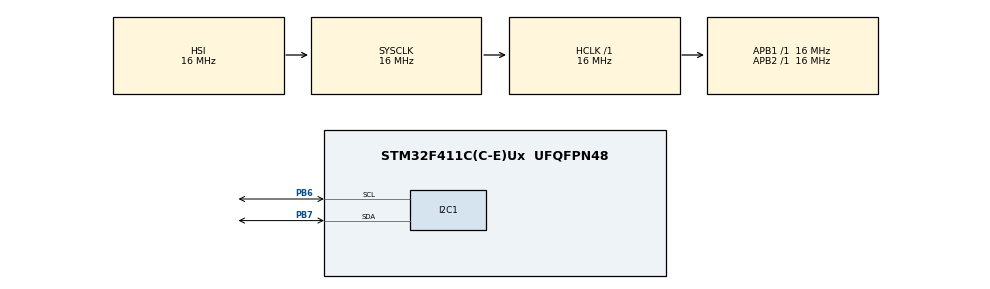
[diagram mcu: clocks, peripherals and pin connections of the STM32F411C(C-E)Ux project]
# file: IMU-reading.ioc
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Mcu.Family=STM32F4
Mcu.Name=STM32F411C(C-E)Ux
Mcu.Package=UFQFPN48
NVIC.PriorityGroup=NVIC_PRIORITYGROUP_4
PB6.Mode=I2C
PB6.Signal=I2C1_SCL
PB7.Mode=I2C
PB7.Signal=I2C1_SDA
ProjectManager.HeapSize=0x200
ProjectManager.StackSize=0x400
ProjectManager.TargetToolchain=STM32CubeIDE
RCC.AHBFreq_Value=16000000
RCC.APB1Freq_Value=16000000
RCC.APB2Freq_Value=16000000
RCC.CortexFreq_Value=16000000
RCC.HSE_VALUE=25000000
RCC.HSI_VALUE=16000000
RCC.LSE_VALUE=32768
RCC.SYSCLKFreq_VALUE=16000000
RCC.VCOOutputFreq_Value=192000000
board=custom

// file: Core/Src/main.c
/* USER CODE BEGIN Header */
/**
 ******************************************************************************
 * @file           : main.c
 * @brief          : Main program body
 ******************************************************************************
 * @attention
 *
 * Copyright (c) 2025 STMicroelectronics.
 * All rights reserved.
 *
 * This software is licensed under terms that can be found in the LICENSE file
 * in the root directory of this software component.
 * If no LICENSE file comes with this software, it is provided AS-IS.
 *
 ******************************************************************************
 */
/* USER CODE END Header */
#include "main.h"

/* USER CODE BEGIN Includes */
#include "lsm6dsox_reg.h"
#include "lis3mdl_reg.h"
/* USER CODE END Includes */

I2C_HandleTypeDef hi2c1;

/* USER CODE BEGIN PV */

uint8_t who_am_i1;

stmdev_ctx_t lsm6dsox_ctx;
stmdev_ctx_t lis3mdl_ctx;

uint8_t test_data = 0xAA;

float accel_x, accel_y, accel_z;
float gyro_x, gyro_y, gyro_z;
float mag_x, mag_y, mag_z;
/* USER CODE END PV */

void SystemClock_Config(void);
static void MX_GPIO_Init(void);
static void MX_I2C1_Init(void);
/* USER CODE BEGIN PFP */
// I2C read and write functions
int32_t platform_write(void *handle, uint8_t reg, const uint8_t *bufp,
		uint16_t len);
int32_t platform_read(void *handle, uint8_t reg, uint8_t *bufp, uint16_t len);

// Initialization functions
void LSM6DSOX_Init(void);
void LIS3MDL_Init(void);

// Sensor data read functions
void LSM6DSOX_ReadAccel(float *x, float *y, float *z);
void LSM6DSOX_ReadGyro(float *x, float *y, float *z);
void LIS3MDL_ReadMag(float *x, float *y, float *z);
/* USER CODE END PFP */

int main(void) {

	/* MCU Configuration--------------------------------------------------------*/

	/* Reset of all peripherals, Initializes the Flash interface and the Systick. */
	HAL_Init();

	/* Configure the system clock */
	SystemClock_Config();

	/* Initialize all configured peripherals */
	MX_GPIO_Init();
	MX_I2C1_Init();
	/* USER CODE BEGIN 2 */
	LSM6DSOX_Init();
	LIS3MDL_Init();
	/* USER CODE END 2 */

	/* Infinite loop */
	while (1) {
		// Variables for sensor readings

		// Read sensor data
		LSM6DSOX_ReadAccel(&accel_x, &accel_y, &accel_z);
		LSM6DSOX_ReadGyro(&gyro_x, &gyro_y, &gyro_z);
		LIS3MDL_ReadMag(&mag_x, &mag_y, &mag_z);

//		test_I2C_Communication();
		HAL_Delay(500);
	}
}

void SystemClock_Config(void) {
	RCC_OscInitTypeDef RCC_OscInitStruct = { 0 };
	RCC_ClkInitTypeDef RCC_ClkInitStruct = { 0 };

	/** Configure the main internal regulator output voltage
	 */
	__HAL_RCC_PWR_CLK_ENABLE();
	__HAL_PWR_VOLTAGESCALING_CONFIG(PWR_REGULATOR_VOLTAGE_SCALE1);

	/** Initializes the RCC Oscillators according to the specified parameters
	 * in the RCC_OscInitTypeDef structure.
	 */
	RCC_OscInitStruct.OscillatorType = RCC_OSCILLATORTYPE_HSI;
	RCC_OscInitStruct.HSIState = RCC_HSI_ON;
	RCC_OscInitStruct.HSICalibrationValue = RCC_HSICALIBRATION_DEFAULT;
	RCC_OscInitStruct.PLL.PLLState = RCC_PLL_NONE;
	if (HAL_RCC_OscConfig(&RCC_OscInitStruct) != HAL_OK) {
		Error_Handler();
	}

	/** Initializes the CPU, AHB and APB buses clocks
	 */
	RCC_ClkInitStruct.ClockType = RCC_CLOCKTYPE_HCLK | RCC_CLOCKTYPE_SYSCLK
			| RCC_CLOCKTYPE_PCLK1 | RCC_CLOCKTYPE_PCLK2;
	RCC_ClkInitStruct.SYSCLKSource = RCC_SYSCLKSOURCE_HSI;
	RCC_ClkInitStruct.AHBCLKDivider = RCC_SYSCLK_DIV1;
	RCC_ClkInitStruct.APB1CLKDivider = RCC_HCLK_DIV1;
	RCC_ClkInitStruct.APB2CLKDivider = RCC_HCLK_DIV1;

	if (HAL_RCC_ClockConfig(&RCC_ClkInitStruct, FLASH_LATENCY_0) != HAL_OK) {
		Error_Handler();
	}
}

static void MX_I2C1_Init(void) {

	hi2c1.Instance = I2C1;
	hi2c1.Init.ClockSpeed = 100000;
	hi2c1.Init.DutyCycle = I2C_DUTYCYCLE_2;
	hi2c1.Init.OwnAddress1 = 0;
	hi2c1.Init.AddressingMode = I2C_ADDRESSINGMODE_7BIT;
	hi2c1.Init.DualAddressMode = I2C_DUALADDRESS_DISABLE;
	hi2c1.Init.OwnAddress2 = 0;
	hi2c1.Init.GeneralCallMode = I2C_GENERALCALL_DISABLE;
	hi2c1.Init.NoStretchMode = I2C_NOSTRETCH_DISABLE;
	if (HAL_I2C_Init(&hi2c1) != HAL_OK) {
		Error_Handler();
	}

}

static void MX_GPIO_Init(void) {

	/* GPIO Ports Clock Enable */
	__HAL_RCC_GPIOB_CLK_ENABLE();

}

/* USER CODE BEGIN 4 */

void test_I2C_Communication() {
    HAL_StatusTypeDef status;

    // 1. Try sending a test byte to the LSM6DSOX address (default: 0x6A)
    uint8_t device_address = 0x6A << 1;  // Shifted for 7-bit address format

    status = HAL_I2C_Master_Transmit(&hi2c1, device_address, &test_data, 1, HAL_MAX_DELAY);

    if (status == HAL_OK) {
        char msg[] = "I2C Write OK\r\n";
//        HAL_UART_Transmit(&huart2, (uint8_t*)msg, sizeof(msg), HAL_MAX_DELAY);
    } else {
        char msg[] = "I2C Write FAIL\r\n";
        //HAL_UART_Transmit(&huart2, (uint8_t*)msg, sizeof(msg), HAL_MAX_DELAY);
    }
}

void LSM6DSOX_Init(void) {

    // Initialize context
    lsm6dsox_ctx.write_reg = platform_write;
    lsm6dsox_ctx.read_reg = platform_read;
    lsm6dsox_ctx.handle = &hi2c1;

    // Check WHO_AM_I register
    lsm6dsox_device_id_get(&lsm6dsox_ctx, &who_am_i1);
    if (who_am_i1 != LSM6DSOX_ID) {
       // while (1);
    }

    // Reset device
    lsm6dsox_reset_set(&lsm6dsox_ctx, PROPERTY_ENABLE);
    uint8_t reset;
    do {
        lsm6dsox_reset_get(&lsm6dsox_ctx, &reset);
    } while (reset);

    // Enable Block Data Update
    lsm6dsox_block_data_update_set(&lsm6dsox_ctx, PROPERTY_ENABLE);

    // Configure accelerometer (2g, 416 Hz)
    lsm6dsox_xl_data_rate_set(&lsm6dsox_ctx, LSM6DSOX_XL_ODR_417Hz);
    lsm6dsox_xl_full_scale_set(&lsm6dsox_ctx, LSM6DSOX_2g);

    // Configure gyroscope (2000 dps, 416 Hz)
    lsm6dsox_gy_data_rate_set(&lsm6dsox_ctx, LSM6DSOX_GY_ODR_417Hz);
    lsm6dsox_gy_full_scale_set(&lsm6dsox_ctx, LSM6DSOX_2000dps);

    printf("LSM6DSOX initialized.\n");
}

/**
 * @brief Initialize the LIS3MDL sensor.
 */
void LIS3MDL_Init(void) {
    uint8_t who_am_i;

    // Initialize context
    lis3mdl_ctx.write_reg = platform_write;
    lis3mdl_ctx.read_reg = platform_read;
    lis3mdl_ctx.handle = &hi2c1;

    // Check WHO_AM_I register
    lis3mdl_device_id_get(&lis3mdl_ctx, &who_am_i);
  //  if (who_am_i != LIS3MDL_ID) {
  //      printf("LIS3MDL not detected! WHO_AM_I=0x%02X\n", who_am_i);
  //      while (1);
  //  }

    // Reset device
    lis3mdl_reset_set(&lis3mdl_ctx, PROPERTY_ENABLE);
    uint8_t reset;
    do {
        lis3mdl_reset_get(&lis3mdl_ctx, &reset);
    } while (reset);

    // Configure magnetometer (Ultra-high performance, 10 Hz)
    lis3mdl_block_data_update_set(&lis3mdl_ctx, PROPERTY_ENABLE);
    lis3mdl_data_rate_set(&lis3mdl_ctx, LIS3MDL_UHP_10Hz);
    lis3mdl_full_scale_set(&lis3mdl_ctx, LIS3MDL_4_GAUSS);
    lis3mdl_operating_mode_set(&lis3mdl_ctx, LIS3MDL_CONTINUOUS_MODE);

    printf("LIS3MDL initialized.\n");
}
/**
 * @brief Read accelerometer data.
 */
void LSM6DSOX_ReadAccel(float *x, float *y, float *z) {
    int16_t data_raw[3];
    lsm6dsox_acceleration_raw_get(&lsm6dsox_ctx, data_raw);
    *x = lsm6dsox_from_fs2_to_mg(data_raw[0]) / 1000.0f;
    *y = lsm6dsox_from_fs2_to_mg(data_raw[1]) / 1000.0f;
    *z = lsm6dsox_from_fs2_to_mg(data_raw[2]) / 1000.0f;
}

/**
 * @brief Read gyroscope data.
 */
void LSM6DSOX_ReadGyro(float *x, float *y, float *z) {
    int16_t data_raw[3];
    lsm6dsox_angular_rate_raw_get(&lsm6dsox_ctx, data_raw);
    *x = lsm6dsox_from_fs2000_to_mdps(data_raw[0]) / 1000.0f;
    *y = lsm6dsox_from_fs2000_to_mdps(data_raw[1]) / 1000.0f;
    *z = lsm6dsox_from_fs2000_to_mdps(data_raw[2]) / 1000.0f;
}

/**
 * @brief Read magnetometer data.
 */
void LIS3MDL_ReadMag(float *x, float *y, float *z) {
    int16_t data_raw[3];
    lis3mdl_magnetic_raw_get(&lis3mdl_ctx, data_raw);
    *x = lis3mdl_from_fs4_to_gauss(data_raw[0]);
    *y = lis3mdl_from_fs4_to_gauss(data_raw[1]);
    *z = lis3mdl_from_fs4_to_gauss(data_raw[2]);
}

/**
 * @brief Platform-specific write function.
 */
int32_t platform_write(void *handle, uint8_t reg, const uint8_t *bufp, uint16_t len) {
}

/**
 * @brief Platform-specific read function.
 */
int32_t platform_read(void *handle, uint8_t reg, uint8_t *bufp, uint16_t len) {
    return HAL_I2C_Mem_Read((I2C_HandleTypeDef *)handle, LSM6DSOX_I2C_ADD_H, reg, I2C_MEMADD_SIZE_8BIT, bufp, len, HAL_MAX_DELAY);
}
/* USER CODE END 4 */

void Error_Handler(void) {
	__disable_irq();
	while (1) {
	}
}
